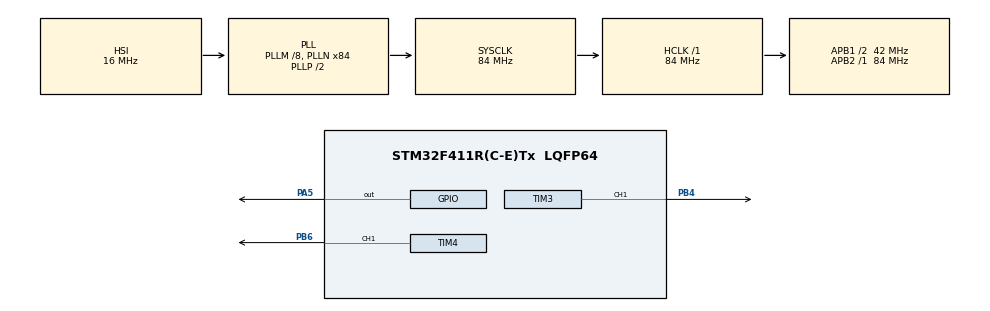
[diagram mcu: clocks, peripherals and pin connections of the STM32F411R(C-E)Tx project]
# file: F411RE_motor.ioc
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Mcu.Family=STM32F4
Mcu.Name=STM32F411R(C-E)Tx
Mcu.Package=LQFP64
NVIC.PriorityGroup=NVIC_PRIORITYGROUP_4
PA5.Signal=GPIO_Output
PB4.Signal=S_TIM3_CH1
PB6.Signal=S_TIM4_CH1
ProjectManager.HeapSize=0x200
ProjectManager.StackSize=0x400
ProjectManager.TargetToolchain=STM32CubeIDE
RCC.48MHZClocksFreq_Value=42000000
RCC.AHBFreq_Value=84000000
RCC.APB1CLKDivider=RCC_HCLK_DIV2
RCC.APB1Freq_Value=42000000
RCC.APB1TimFreq_Value=84000000
RCC.APB2Freq_Value=84000000
RCC.APB2TimFreq_Value=84000000
RCC.CortexFreq_Value=84000000
RCC.HCLKFreq_Value=84000000
RCC.HSE_VALUE=25000000
RCC.HSI_VALUE=16000000
RCC.LSE_VALUE=32768
RCC.PLLM=8
RCC.PLLN=84
RCC.SYSCLKFreq_VALUE=84000000
RCC.SYSCLKSource=RCC_SYSCLKSOURCE_PLLCLK
RCC.VCOOutputFreq_Value=168000000
SH.S_TIM3_CH1.0=TIM3_CH1,PWM Generation1 CH1
SH.S_TIM4_CH1.0=TIM4_CH1,PWM Generation1 CH1
TIM2.Period=335
TIM2.Prescaler=9
TIM3.Channel-PWM\ Generation1\ CH1=TIM_CHANNEL_1
TIM3.Period=335
TIM3.Prescaler=9
TIM4.Channel-PWM\ Generation1\ CH1=TIM_CHANNEL_1
TIM4.Period=335
TIM4.Prescaler=9
VP_TIM2_VS_ClockSourceINT.Mode=Internal
VP_TIM3_VS_ClockSourceINT.Mode=Internal
VP_TIM4_VS_ClockSourceINT.Mode=Internal
board=custom

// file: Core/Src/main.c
/* USER CODE BEGIN Header */
/**
  ******************************************************************************
  * @file           : main.c
  * @brief          : Main program body
  ******************************************************************************
  * @attention
  *
  * Copyright (c) 2024 STMicroelectronics.
  * All rights reserved.
  *
  * This software is licensed under terms that can be found in the LICENSE file
  * in the root directory of this software component.
  * If no LICENSE file comes with this software, it is provided AS-IS.
  *
  ******************************************************************************
  */
/* USER CODE END Header */
#include "main.h"

TIM_HandleTypeDef htim2;
TIM_HandleTypeDef htim3;
TIM_HandleTypeDef htim4;

void SystemClock_Config(void);
static void MX_GPIO_Init(void);
static void MX_TIM2_Init(void);
static void MX_TIM3_Init(void);
static void MX_TIM4_Init(void);

int main(void)
{

  /* MCU Configuration--------------------------------------------------------*/

  /* Reset of all peripherals, Initializes the Flash interface and the Systick. */
  HAL_Init();

  /* Configure the system clock */
  SystemClock_Config();

  /* Initialize all configured peripherals */
  MX_GPIO_Init();
  MX_TIM2_Init();
  MX_TIM3_Init();
  MX_TIM4_Init();
  /* USER CODE BEGIN 2 */

  // Set an initial duty cycle for the PWM pins
  uint32_t duty_cycle_d5 = 30;
  uint32_t duty_cycle_d6 = 30;
  uint32_t new_duty_cycle = 70;

  // Set the duty cycle values (outside the while loop)
  __HAL_TIM_SET_COMPARE(&htim3, TIM_CHANNEL_1, duty_cycle_d5);
  __HAL_TIM_SET_COMPARE(&htim4, TIM_CHANNEL_1, duty_cycle_d6);

  // Start the PWM on both channels
  HAL_TIM_PWM_Start(&htim3, TIM_CHANNEL_1); // Start PWM on PB4 (D5)
  HAL_TIM_PWM_Start(&htim4, TIM_CHANNEL_1); // Start PWM on PB10 (D6)

  /* USER CODE END 2 */

  /* Infinite loop */
  while (1)
  {
	  HAL_GPIO_WritePin(GPIOA, GPIO_PIN_5, 1);

	  __HAL_TIM_SET_COMPARE(&htim3, TIM_CHANNEL_1, new_duty_cycle);
	  __HAL_TIM_SET_COMPARE(&htim4, TIM_CHANNEL_1, 0);
	  HAL_Delay(4000);

	  HAL_GPIO_WritePin(GPIOA, GPIO_PIN_5, 0);
	  // turn off motor
	  __HAL_TIM_SET_COMPARE(&htim3, TIM_CHANNEL_1, 0);
	  __HAL_TIM_SET_COMPARE(&htim4, TIM_CHANNEL_1, 0);
	  HAL_Delay(4000);

	  HAL_GPIO_WritePin(GPIOA, GPIO_PIN_5, 1);
	  __HAL_TIM_SET_COMPARE(&htim3, TIM_CHANNEL_1, 0);
	  __HAL_TIM_SET_COMPARE(&htim4, TIM_CHANNEL_1, new_duty_cycle);
	  HAL_Delay(4000);

	  HAL_GPIO_WritePin(GPIOA, GPIO_PIN_5, 0);
  }
}

void SystemClock_Config(void)
{
  RCC_OscInitTypeDef RCC_OscInitStruct = {0};
  RCC_ClkInitTypeDef RCC_ClkInitStruct = {0};

  /** Configure the main internal regulator output voltage
  */
  __HAL_RCC_PWR_CLK_ENABLE();
  __HAL_PWR_VOLTAGESCALING_CONFIG(PWR_REGULATOR_VOLTAGE_SCALE1);

  /** Initializes the RCC Oscillators according to the specified parameters
  * in the RCC_OscInitTypeDef structure.
  */
  RCC_OscInitStruct.OscillatorType = RCC_OSCILLATORTYPE_HSI;
  RCC_OscInitStruct.HSIState = RCC_HSI_ON;
  RCC_OscInitStruct.HSICalibrationValue = RCC_HSICALIBRATION_DEFAULT;
  RCC_OscInitStruct.PLL.PLLState = RCC_PLL_ON;
  RCC_OscInitStruct.PLL.PLLSource = RCC_PLLSOURCE_HSI;
  RCC_OscInitStruct.PLL.PLLM = 8;
  RCC_OscInitStruct.PLL.PLLN = 84;
  RCC_OscInitStruct.PLL.PLLP = RCC_PLLP_DIV2;
  RCC_OscInitStruct.PLL.PLLQ = 4;
  if (HAL_RCC_OscConfig(&RCC_OscInitStruct) != HAL_OK)
  {
    Error_Handler();
  }

  /** Initializes the CPU, AHB and APB buses clocks
  */
  RCC_ClkInitStruct.ClockType = RCC_CLOCKTYPE_HCLK|RCC_CLOCKTYPE_SYSCLK
                              |RCC_CLOCKTYPE_PCLK1|RCC_CLOCKTYPE_PCLK2;
  RCC_ClkInitStruct.SYSCLKSource = RCC_SYSCLKSOURCE_PLLCLK;
  RCC_ClkInitStruct.AHBCLKDivider = RCC_SYSCLK_DIV1;
  RCC_ClkInitStruct.APB1CLKDivider = RCC_HCLK_DIV2;
  RCC_ClkInitStruct.APB2CLKDivider = RCC_HCLK_DIV1;

  if (HAL_RCC_ClockConfig(&RCC_ClkInitStruct, FLASH_LATENCY_2) != HAL_OK)
  {
    Error_Handler();
  }
}

static void MX_TIM2_Init(void)
{

  TIM_ClockConfigTypeDef sClockSourceConfig = {0};
  TIM_MasterConfigTypeDef sMasterConfig = {0};

  htim2.Instance = TIM2;
  htim2.Init.Prescaler = 9;
  htim2.Init.CounterMode = TIM_COUNTERMODE_UP;
  htim2.Init.Period = 335;
  htim2.Init.ClockDivision = TIM_CLOCKDIVISION_DIV1;
  htim2.Init.AutoReloadPreload = TIM_AUTORELOAD_PRELOAD_DISABLE;
  if (HAL_TIM_Base_Init(&htim2) != HAL_OK)
  {
    Error_Handler();
  }
  sClockSourceConfig.ClockSource = TIM_CLOCKSOURCE_INTERNAL;
  if (HAL_TIM_ConfigClockSource(&htim2, &sClockSourceConfig) != HAL_OK)
  {
    Error_Handler();
  }
  sMasterConfig.MasterOutputTrigger = TIM_TRGO_RESET;
  sMasterConfig.MasterSlaveMode = TIM_MASTERSLAVEMODE_DISABLE;
  if (HAL_TIMEx_MasterConfigSynchronization(&htim2, &sMasterConfig) != HAL_OK)
  {
    Error_Handler();
  }

}

static void MX_TIM3_Init(void)
{

  TIM_ClockConfigTypeDef sClockSourceConfig = {0};
  TIM_MasterConfigTypeDef sMasterConfig = {0};
  TIM_OC_InitTypeDef sConfigOC = {0};

  htim3.Instance = TIM3;
  htim3.Init.Prescaler = 9;
  htim3.Init.CounterMode = TIM_COUNTERMODE_UP;
  htim3.Init.Period = 335;
  htim3.Init.ClockDivision = TIM_CLOCKDIVISION_DIV1;
  htim3.Init.AutoReloadPreload = TIM_AUTORELOAD_PRELOAD_DISABLE;
  if (HAL_TIM_Base_Init(&htim3) != HAL_OK)
  {
    Error_Handler();
  }
  sClockSourceConfig.ClockSource = TIM_CLOCKSOURCE_INTERNAL;
  if (HAL_TIM_ConfigClockSource(&htim3, &sClockSourceConfig) != HAL_OK)
  {
    Error_Handler();
  }
  if (HAL_TIM_PWM_Init(&htim3) != HAL_OK)
  {
    Error_Handler();
  }
  sMasterConfig.MasterOutputTrigger = TIM_TRGO_RESET;
  sMasterConfig.MasterSlaveMode = TIM_MASTERSLAVEMODE_DISABLE;
  if (HAL_TIMEx_MasterConfigSynchronization(&htim3, &sMasterConfig) != HAL_OK)
  {
    Error_Handler();
  }
  sConfigOC.OCMode = TIM_OCMODE_PWM1;
  sConfigOC.Pulse = 0;
  sConfigOC.OCPolarity = TIM_OCPOLARITY_HIGH;
  sConfigOC.OCFastMode = TIM_OCFAST_DISABLE;
  if (HAL_TIM_PWM_ConfigChannel(&htim3, &sConfigOC, TIM_CHANNEL_1) != HAL_OK)
  {
    Error_Handler();
  }
  HAL_TIM_MspPostInit(&htim3);

}

static void MX_TIM4_Init(void)
{

  TIM_ClockConfigTypeDef sClockSourceConfig = {0};
  TIM_MasterConfigTypeDef sMasterConfig = {0};
  TIM_OC_InitTypeDef sConfigOC = {0};

  htim4.Instance = TIM4;
  htim4.Init.Prescaler = 9;
  htim4.Init.CounterMode = TIM_COUNTERMODE_UP;
  htim4.Init.Period = 335;
  htim4.Init.ClockDivision = TIM_CLOCKDIVISION_DIV1;
  htim4.Init.AutoReloadPreload = TIM_AUTORELOAD_PRELOAD_DISABLE;
  if (HAL_TIM_Base_Init(&htim4) != HAL_OK)
  {
    Error_Handler();
  }
  sClockSourceConfig.ClockSource = TIM_CLOCKSOURCE_INTERNAL;
  if (HAL_TIM_ConfigClockSource(&htim4, &sClockSourceConfig) != HAL_OK)
  {
    Error_Handler();
  }
  if (HAL_TIM_PWM_Init(&htim4) != HAL_OK)
  {
    Error_Handler();
  }
  sMasterConfig.MasterOutputTrigger = TIM_TRGO_RESET;
  sMasterConfig.MasterSlaveMode = TIM_MASTERSLAVEMODE_DISABLE;
  if (HAL_TIMEx_MasterConfigSynchronization(&htim4, &sMasterConfig) != HAL_OK)
  {
    Error_Handler();
  }
  sConfigOC.OCMode = TIM_OCMODE_PWM1;
  sConfigOC.Pulse = 0;
  sConfigOC.OCPolarity = TIM_OCPOLARITY_HIGH;
  sConfigOC.OCFastMode = TIM_OCFAST_DISABLE;
  if (HAL_TIM_PWM_ConfigChannel(&htim4, &sConfigOC, TIM_CHANNEL_1) != HAL_OK)
  {
    Error_Handler();
  }
  HAL_TIM_MspPostInit(&htim4);

}

static void MX_GPIO_Init(void)
{
  GPIO_InitTypeDef GPIO_InitStruct = {0};

  /* GPIO Ports Clock Enable */
  __HAL_RCC_GPIOA_CLK_ENABLE();
  __HAL_RCC_GPIOB_CLK_ENABLE();

  /*Configure GPIO pin Output Level */
  HAL_GPIO_WritePin(GPIOA, GPIO_PIN_5, GPIO_PIN_RESET);

  /*Configure GPIO pin : PA5 */
  GPIO_InitStruct.Pin = GPIO_PIN_5;
  GPIO_InitStruct.Mode = GPIO_MODE_OUTPUT_PP;
  GPIO_InitStruct.Pull = GPIO_NOPULL;
  GPIO_InitStruct.Speed = GPIO_SPEED_FREQ_LOW;
  HAL_GPIO_Init(GPIOA, &GPIO_InitStruct);

}

void Error_Handler(void)
{
  __disable_irq();
  while (1)
  {
  }
}
